# STM32U335 register map
File version: 1.0
CPU: CM33 r0p1, little endian, MPU, FPU, 4 interrupt priority bits
Registers are 32-bit, read-write, reset 0x0 unless marked. A register's access mark holds for its fields unless they carry their own. Offsets are from the block's base; [hi:lo] are bit positions; {n}, {i} and the like mark numbered series; 'fields as' and 'values as' point back to an identical list.

## RAMCFG — RAMCFG register block
Base 0x40026000
Same registers: RAMCFG_S 0x50026000
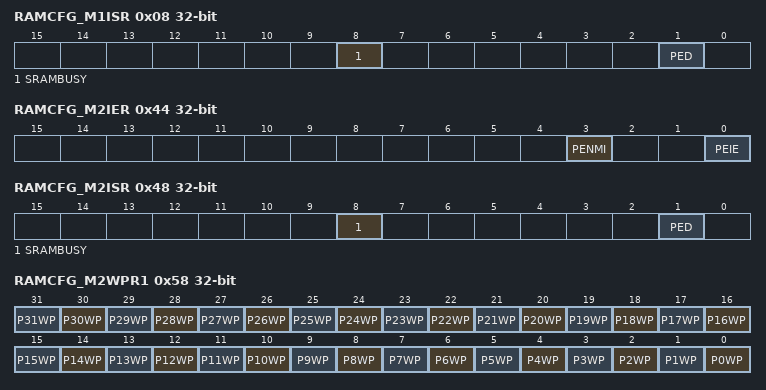
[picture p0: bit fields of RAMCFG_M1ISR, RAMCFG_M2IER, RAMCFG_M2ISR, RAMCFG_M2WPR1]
0x08 RAMCFG_M1ISR ro
  [8] SRAMBUSY — SRAM busy with erase operation
    0=No erase operation ongoing; 1=Erase operation ongoing
  [1] PED — Parity error detected Note: This bit is reserved and must be kept at reset value in SRAM1 control registers.
    0=No Parity error detected; 1=Parity error detected
0x28 RAMCFG_M1ERKEYR wo
  [7:0] ERASEKEY — Erase write protection key The following steps are required to unlock the write protection of SRAMER in RAMCFG_MxCR. 1) Write 0xCA into ERASEKEY[7:0]. 2) Write 0x53 into ERASEKEY[7:0]. Note: Writing a wrong key reactivates the write protection.
0x44 RAMCFG_M2IER
  [3] PENMI — Parity error NMI This bit is set by software and cleared only by a global RAMCFG reset. Note: If this bit is set, the RAMCFG maskable interrupt is not generated whatever PEIE value.
    0=NMI not generated in case of Parity error; 1=NMI generated in case of Parity error
  [0] PEIE — Parity error interrupt enable
    0=Parity error interrupt disabled; 1=Parity error interrupt enabled
0x48 RAMCFG_M2ISR ro
  fields as RAMCFG_M1ISR
0x50 RAMCFG_M2PEAR ro
  [31:0] PEA — Parity error address When the ALE bit is set in RAMCFG_MxCR, this bit field is updated with the address corresponding to the parity error.
0x54 RAMCFG_M2ICR
  [1] CPED — Clear parity error detected Writing 1 to this flag clears PED bit in RAMCFG_MxISR. Reading this flag returns the PED value.
0x58 RAMCFG_M2WPR1
  [all] fields
    0=Write protection of SRAM2 1-Kbyte page y is disabled; 1=Write protection of SRAM2 1-Kbyte page y is enabled
  [n] P{n}WP (n=0..31) — SRAM2 1-Kbyte page y write protection These bits are set by software and cleared only by a global RAMCFG reset.
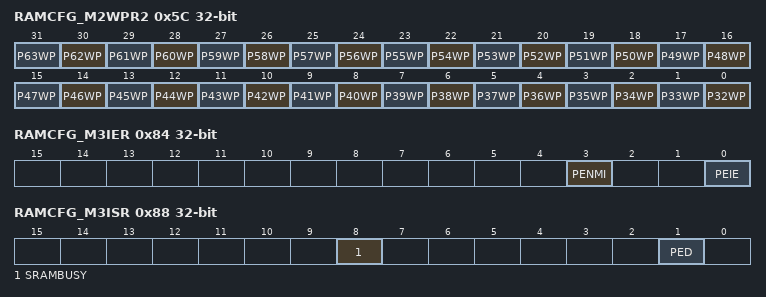
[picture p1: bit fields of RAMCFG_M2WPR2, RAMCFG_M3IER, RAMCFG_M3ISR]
0x5C RAMCFG_M2WPR2
  [all] fields
    values as the fields of RAMCFG_M2WPR1
  [n-32] P{n}WP (n=32..63) — SRAM2 1-Kbyte page y write protection These bits are set by software and cleared only by a global RAMCFG reset.
0x64 RAMCFG_M2PARKEYR wo
  [7:0] PARKEY — Parity write protection key The following steps are required to unlock the write protection of PCE in RAMCFG_MxCR. 1) Write 0xAE into PARKEY[7:0]. 2) Write 0x75 into PARKEY[7:0]. Note: Writing a wrong key reactivates the write protection.
0x68 RAMCFG_M2ERKEYR wo
  fields as RAMCFG_M1ERKEYR
0x84 RAMCFG_M3IER
  fields as RAMCFG_M2IER
0x88 RAMCFG_M3ISR ro
  fields as RAMCFG_M1ISR
0x90 RAMCFG_M3PEAR ro
  fields as RAMCFG_M2PEAR
0x94 RAMCFG_M3ICR
  fields as RAMCFG_M2ICR
0xA4 RAMCFG_M3PARKEYR wo
  fields as RAMCFG_M2PARKEYR
0xA8 RAMCFG_M3ERKEYR wo
  fields as RAMCFG_M1ERKEYR

## RNG — RNG address block description
Base 0x420C0800
Same registers: RNG_S 0x520C0800
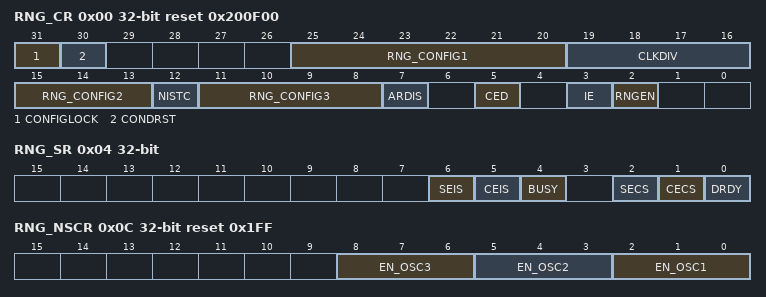
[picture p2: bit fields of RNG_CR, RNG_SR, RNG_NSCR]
0x00 RNG_CR reset 0x200F00 — RNG control register
  [31] CONFIGLOCK — RNG Config lock
    0=Writes to the RNG_NSCR, RNG_HTCR and the RNG_CR configuration bits [29:4] are allowed; 1=Writes to the RNG_NSCR, RNG_HTCR and the RNG_CR configuration bits [29:4] are ignored until the next RNG reset
  [30] CONDRST — Conditioning soft reset
  [25:20] RNG_CONFIG1 — RNG configuration 1
  [19:16] CLKDIV — Clock divider factor
    0=internal RNG clock after divider is similar to incoming RNG clock; 1=two RNG clock cycles per internal RNG clock; 2=2less thansup>2less than/sup> (= 4) RNG clock cycles per internal RNG clock; 15=2less thansup>15less than/sup> RNG clock cycles per internal clock (for example
  [15:13] RNG_CONFIG2 — RNG configuration 2
  [12] NISTC — NIST custom
    0=Hardware default values for NIST compliant RNG; 1=Custom values for NIST compliant RNG
  [11:8] RNG_CONFIG3 — RNG configuration 3
  [7] ARDIS — Auto reset disable
    0=Auto-reset is enabled; 1=Auto-reset is disabled
  [5] CED — Clock error detection
    0=Clock error detection is enabled; 1=Clock error detection is disabled
  [3] IE — Interrupt enable
    0=RNG interrupt is disabled; 1=RNG interrupt is enabled
  [2] RNGEN — True random number generator enable
    0=True random number generator disabled; 1=True random number generator enabled
0x04 RNG_SR — RNG status register
  [6] SEIS — Seed error interrupt status
    0=No faulty sequence detected; 1=At least one faulty sequence is detected
  [5] CEIS — Clock error interrupt status
    0=The RNG clock is correct (fless thansub>RNGCLKless than/sub>> fless thansub>HCLKless than/sub>/32); 1=The RNG clock before the internal divider is detected too slow (fless thansub>RNGCLKless than/sub>less than fless thansub>HCLKless than/sub>/32)
  [4] BUSY ro
    0=Idle; 1=Busy
  [2] SECS ro — Seed error current status
    0=No faulty sequence has currently been detected; 1=At least one of the following faulty sequence has been detected:
  [1] CECS ro — Clock error current status
    0=The RNG clock is correct (fless thansub>RNGCLKless than/sub>> fless thansub>HCLKless than/sub>/32); 1=The RNG clock is too slow (fless thansub>RNGCLKless than/sub>less than fless thansub>HCLKless than/sub>/32)
  [0] DRDY ro — Data ready
    0=No valid random data ready; 1=Valid random data ready
0x08 RNG_DR ro — RNG data register
  [31:0] RNDATA — Random data
0x0C RNG_NSCR reset 0x1FF — RNG noise source control register
  [8:6] EN_OSC3 — Each bit drives one oscillator enable signal input of instance number 3, gated with the RNGEN bit in RNG_CR (set bit to enable the oscillator).
  [5:3] EN_OSC2 — Each bit drives one oscillator enable signal input of instance number 2, gated with the RNGEN bit in RNG_CR (set bit to enable the oscillator).
  [2:0] EN_OSC1 — Each bit drives one oscillator enable signal input of instance number 1, gated with the RNGEN bit in RNG_CR (set bit to enable the oscillator).
0x10 RNG_HTCR0 reset 0x72AC — RNG health test control register 0
  [31:0] HTCFG — health test configuration
{0x10+4i} RNG_HTCR{i} reset 0xFFFF (i=1..3) — RNG health test control register {i}
  [31:0] HTCFG — health test configuration

## TIM6 — TIM6 address block description
Base 0x40001000
Same registers: TIM6_S 0x50001000
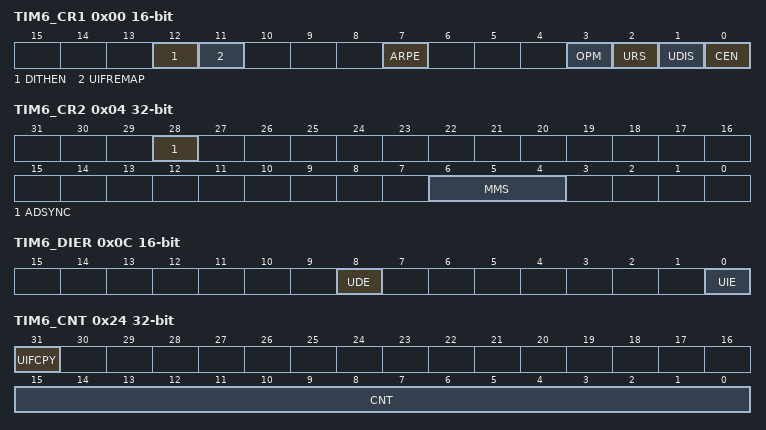
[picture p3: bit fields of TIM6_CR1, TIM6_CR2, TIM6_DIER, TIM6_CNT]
0x00 TIM6_CR1 16-bit — TIM6 control register 1
  [12] DITHEN — Dithering enable
    0=Dithering disabled; 1=Dithering enabled
  [11] UIFREMAP — UIF status bit remapping
    0=No remapping; 1=Remapping enabled
  [7] ARPE — Auto-reload preload enable
    0=TIMx_ARR register is not buffered; 1=TIMx_ARR register is buffered
  [3] OPM — One-pulse mode
    0=Counter is not stopped at update event; 1=Counter stops counting at the next update event (clearing the CEN bit)
  [2] URS — Update request source
    0=Any of the following events generates an update interrupt or DMA request if enabled; 1=Only counter overflow/underflow generates an update interrupt or DMA request if enabled
  [1] UDIS — Update disable
    0=UEV enabled; 1=UEV disabled
  [0] CEN — Counter enable
    0=Counter disabled; 1=Counter enabled
0x04 TIM6_CR2 — TIM6 control register 2
  [28] ADSYNC — ADC synchronization
    0=The timer operates independently from the ADC; 1=The timer operation is synchronized with the ADC clock to provide jitter-free sampling point
  [6:4] MMS — Master mode selection
    0=Reset-the UG bit from the TIMx_EGR register is used as a trigger output (tim_trgo); 1=Enable-the Counter enable signal, tim_cnt_en, is used as a trigger output (tim_trgo); 2=Update-The update event is selected as a trigger output (tim_trgo)
0x0C TIM6_DIER 16-bit — TIM6 DMA/Interrupt enable register
  [8] UDE — Update DMA request enable
    0=Update DMA request disabled; 1=Update DMA request enabled
  [0] UIE — Update interrupt enable
    0=Update interrupt disabled; 1=Update interrupt enabled
0x10 TIM6_SR 16-bit — TIM6 status register
  [0] UIF — Update interrupt flag
    0=No update occurred; 1=Update interrupt pending
0x14 TIM6_EGR 16-bit wo — TIM6 event generation register
  [0] UG — Update generation
    0=No action; 1=Re-initializes the timer counter and generates an update of the registers
0x24 TIM6_CNT — TIM6 counter
  [31] UIFCPY ro — UIF copy
  [15:0] CNT — Counter value
0x28 TIM6_PSC 16-bit — TIM6 prescaler
  [15:0] PSC — Prescaler value
0x2C TIM6_ARR reset 0xFFFF — TIM6 autoreload register
  [19:0] ARR — Auto-reload value

## TIM7 — TIM7 address block description
Base 0x40001400
Same registers: TIM7_S 0x50001400
Registers as TIM6 (with TIM6 read as TIM7).

## WWDG — WWDG address block description
Base 0x40002C00
Same registers: WWDG_S 0x50002C00
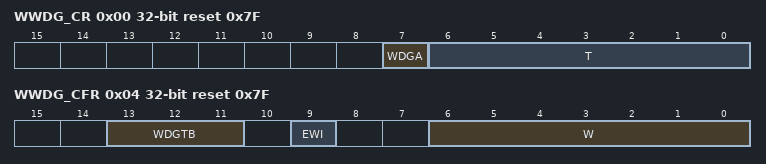
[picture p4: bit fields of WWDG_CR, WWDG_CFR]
0x00 WWDG_CR reset 0x7F — WWDG control register
  [7] WDGA — Activation bit
    0=Watchdog disabled; 1=Watchdog enabled
  [6:0] T — 7-bit counter (MSB to LSB)
0x04 WWDG_CFR reset 0x7F — WWDG configuration register
  [13:11] WDGTB — Timer base
    0=CK counter clock (PCLK div 4096) div 1; 1=CK counter clock (PCLK div 4096) div 2; 2=CK counter clock (PCLK div 4096) div 4; 3=CK counter clock (PCLK div 4096) div 8; 4=CK counter clock (PCLK div 4096) div 16; 5=CK counter clock (PCLK div 4096) div 32; 6=CK counter clock (PCLK div 4096) div 64; 7=CK counter clock (PCLK div 4096) div 128
  [9] EWI — Early wake-up interrupt enable
  [6:0] W — 7-bit window value
0x08 WWDG_SR — WWDG status register
  [0] EWIF — Early wake-up interrupt flag
